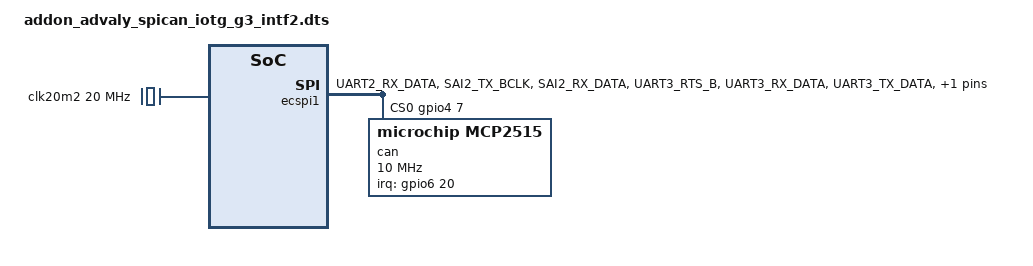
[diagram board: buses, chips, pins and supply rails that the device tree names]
/*
 * Copyright (C) 2019 Atmark Techno, Inc. All Rights Reserved.
 * Author: Daisuke Mizobuchi <mizo@atmark-techno.com>
 *
 * This program is free software; you can redistribute it and/or
 * modify it under the terms of the GNU General Public License
 * version 2 as published by the Free Software Foundation.
 */

#include <dt-bindings/clock/imx7d-clock.h>
#include <dt-bindings/interrupt-controller/irq.h>
#include "../../../../arch/arm/boot/dts/imx7d-pinfunc.h"

/dts-v1/;
/plugin/;
/ {
	fragment@0 {
		target = <&iomuxc>;
		__overlay__ {
			addon-intf2 {
				pinctrl_ecspi1: ecspi1grp {
					fsl,pins = <
						MX7D_PAD_UART2_RX_DATA__GPIO4_IO2	0x00	/* INTF2_32 */
						MX7D_PAD_SAI2_TX_BCLK__GPIO6_IO20	0x70	/* INTF2_47 */
						MX7D_PAD_SAI2_RX_DATA__GPIO6_IO21	0x00	/* INTF2_48 */

						MX7D_PAD_UART3_RTS_B__ECSPI1_SCLK	0x70	/* INTF2_35 */
						MX7D_PAD_UART3_RX_DATA__ECSPI1_MISO	0x70	/* INTF2_36 */
						MX7D_PAD_UART3_TX_DATA__ECSPI1_MOSI	0x70	/* INTF2_37 */
						MX7D_PAD_UART3_CTS_B__GPIO4_IO7		0x70	/* INTF2_50 */
					>;
				};
			};
		};
	};

	fragment@1 {
		target-path = "/";
		__overlay__ {
			clk20m2: dummy@2 {
				compatible = "fixed-clock";
				#clock-cells = <0>;
				clock-frequency = <20000000>;
				clock-output-names = "clk20m2";
			};
		};
	};

	fragment@2 {
		target = <&ecspi1>;
		__overlay__ {
			pinctrl-names = "default";
			pinctrl-0 = <&pinctrl_ecspi1>;
			fsl,spi-num-chipselects = <1>;
			cs-gpios = <&gpio4 7 0>;
			status = "okay";

			#address-cells = <1>;
			#size-cells = <0>;
			can@0 {
				compatible = "microchip,mcp2515";
				reg = <0>;
				clocks = <&clk20m2>;
				spi-max-frequency = <10000000>;
				interrupt-parent = <&gpio6>;
				interrupts = <20 IRQ_TYPE_EDGE_FALLING>;
			};
		};
	};
};
